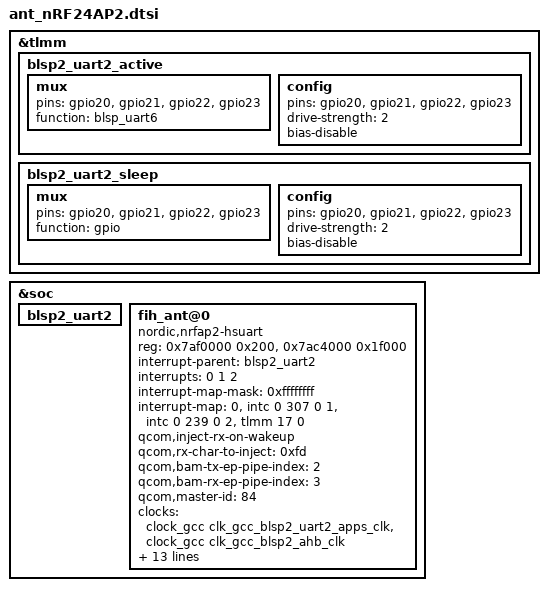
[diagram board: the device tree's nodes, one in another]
&tlmm {

    blsp2_uart2_active: blsp2_uart2_active {
        mux {
            pins = "gpio20", "gpio21", "gpio22", "gpio23";
            function = "blsp_uart6";
        };

        config {
            pins = "gpio20", "gpio21", "gpio22", "gpio23";
            drive-strength = <2>;
            bias-disable;
        };
    };

    blsp2_uart2_sleep: blsp2_uart2_sleep {
        mux {
            pins = "gpio20", "gpio21", "gpio22", "gpio23";
            function = "gpio";
        };

        config {
            pins = "gpio20", "gpio21", "gpio22", "gpio23";
            drive-strength = <2>;
            bias-disable;
        };
    };

};

&soc {

    blsp2_uart2 {
		status = "okay";
    };
    
    fih_ant@0{
        status = "ok";
        compatible = "nordic,nrfap2-hsuart";
        //reg = <0>;
        reg = <0x7af0000 0x200>, 
              <0x7ac4000 0x1f000>;
		reg-names = "core_mem", "bam_mem";
        
		interrupt-names = "core_irq", "bam_irq", "wakeup_irq";
		#address-cells = <0>;
		interrupt-parent = <&blsp2_uart2>;
		interrupts = <0 1 2>;
		#interrupt-cells = <1>;
		interrupt-map-mask = <0xffffffff>;
		interrupt-map = <0 &intc 0 307 0
				1 &intc 0 239 0
				2 &tlmm 17 0>;
                
		qcom,inject-rx-on-wakeup;
		qcom,rx-char-to-inject = <0xfd>;

		qcom,bam-tx-ep-pipe-index = <2>;
		qcom,bam-rx-ep-pipe-index = <3>;
		qcom,master-id = <84>;
        
        clock-names = "core_clk", "iface_clk";
        clocks = <&clock_gcc clk_gcc_blsp2_uart2_apps_clk>,
                 <&clock_gcc clk_gcc_blsp2_ahb_clk>;
            
        pinctrl-names = "sleep", "default";
        pinctrl-0 = <&blsp2_uart2_sleep>;
        pinctrl-1 = <&blsp2_uart2_active>;
        
		qcom,msm-bus,name = "blsp2_uart2";
		qcom,msm-bus,num-cases = <2>;
		qcom,msm-bus,num-paths = <1>;
		qcom,msm-bus,vectors-KBps =
				<84 512 0 0>,
				<84 512 500 800>;

        fih_ant,ANT_UART_TX_MSM = <&tlmm 20 0x00>;
        fih_ant,ANT_UART_RX_MSM = <&tlmm 21 0x00>;
        fih_ant,ANT_UART_RTS_MSM = <&tlmm 22 0x00>;
        
        fih_ant,ANT_GPIO_SUSPEND  = <&tlmm 12 0x00>;
        fih_ant,ANT_GPIO_SLEEP  = <&tlmm 13 0x00>;
        
        vcc_ana-supply = <&pm8953_l15>;
    };

};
